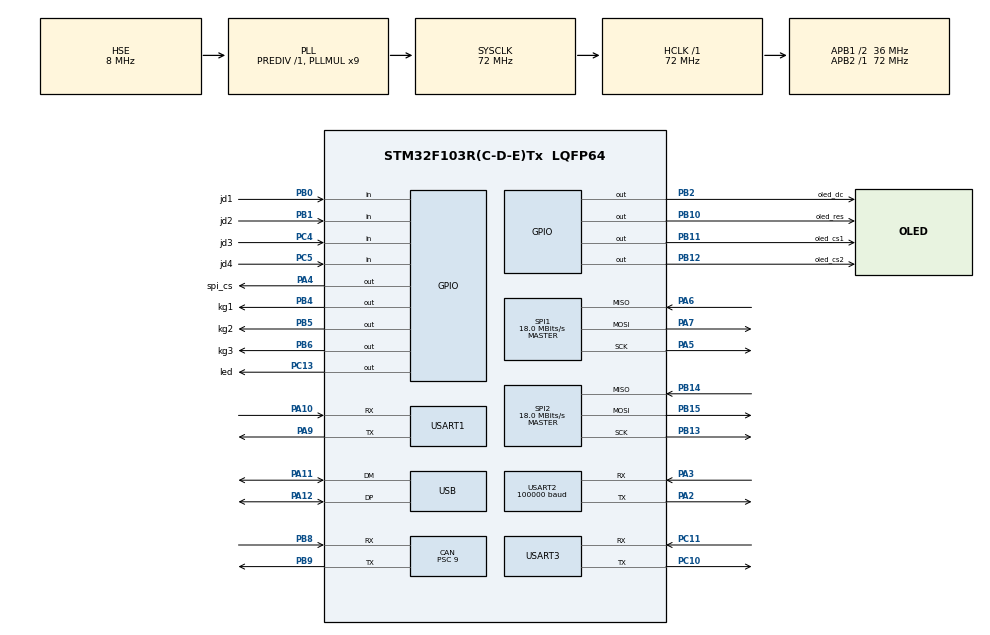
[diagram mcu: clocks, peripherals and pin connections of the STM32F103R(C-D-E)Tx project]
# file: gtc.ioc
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CAN.ABOM=ENABLE
CAN.AWUM=ENABLE
CAN.BS1=CAN_BS1_5TQ
CAN.BS2=CAN_BS2_2TQ
CAN.CalculateBaudRate=500000
CAN.CalculateTimeBit=2000
CAN.CalculateTimeQuantum=250.0
CAN.NART=ENABLE
CAN.Prescaler=9
CAN.SJW=CAN_SJW_1TQ
CAN.TTCM=DISABLE
CAN.TXFP=ENABLE
Dma.Request0=USART1_RX
Dma.Request1=USART1_TX
Dma.Request2=USART2_RX
Dma.Request3=USART3_RX
Dma.Request4=USART3_TX
Dma.USART1_RX.0.Direction=DMA_PERIPH_TO_MEMORY
Dma.USART1_RX.0.Instance=DMA1_Channel5
Dma.USART1_RX.0.MemDataAlignment=DMA_MDATAALIGN_BYTE
Dma.USART1_RX.0.MemInc=DMA_MINC_ENABLE
Dma.USART1_RX.0.Mode=DMA_CIRCULAR
Dma.USART1_RX.0.PeriphDataAlignment=DMA_PDATAALIGN_BYTE
Dma.USART1_RX.0.PeriphInc=DMA_PINC_DISABLE
Dma.USART1_RX.0.Priority=DMA_PRIORITY_LOW
Dma.USART1_TX.1.Direction=DMA_MEMORY_TO_PERIPH
Dma.USART1_TX.1.Instance=DMA1_Channel4
Dma.USART1_TX.1.MemDataAlignment=DMA_MDATAALIGN_BYTE
Dma.USART1_TX.1.MemInc=DMA_MINC_ENABLE
Dma.USART1_TX.1.Mode=DMA_NORMAL
Dma.USART1_TX.1.PeriphDataAlignment=DMA_PDATAALIGN_BYTE
Dma.USART1_TX.1.PeriphInc=DMA_PINC_DISABLE
Dma.USART1_TX.1.Priority=DMA_PRIORITY_LOW
Dma.USART2_RX.2.Direction=DMA_PERIPH_TO_MEMORY
Dma.USART2_RX.2.Instance=DMA1_Channel6
Dma.USART2_RX.2.MemDataAlignment=DMA_MDATAALIGN_BYTE
Dma.USART2_RX.2.MemInc=DMA_MINC_ENABLE
Dma.USART2_RX.2.Mode=DMA_CIRCULAR
Dma.USART2_RX.2.PeriphDataAlignment=DMA_PDATAALIGN_BYTE
Dma.USART2_RX.2.PeriphInc=DMA_PINC_DISABLE
Dma.USART2_RX.2.Priority=DMA_PRIORITY_LOW
Dma.USART3_RX.3.Direction=DMA_PERIPH_TO_MEMORY
Dma.USART3_RX.3.Instance=DMA1_Channel3
Dma.USART3_RX.3.MemDataAlignment=DMA_MDATAALIGN_BYTE
Dma.USART3_RX.3.MemInc=DMA_MINC_ENABLE
Dma.USART3_RX.3.Mode=DMA_NORMAL
Dma.USART3_RX.3.PeriphDataAlignment=DMA_PDATAALIGN_BYTE
Dma.USART3_RX.3.PeriphInc=DMA_PINC_DISABLE
Dma.USART3_RX.3.Priority=DMA_PRIORITY_LOW
Dma.USART3_TX.4.Direction=DMA_MEMORY_TO_PERIPH
Dma.USART3_TX.4.Instance=DMA1_Channel2
Dma.USART3_TX.4.MemDataAlignment=DMA_MDATAALIGN_BYTE
Dma.USART3_TX.4.MemInc=DMA_MINC_ENABLE
Dma.USART3_TX.4.Mode=DMA_CIRCULAR
Dma.USART3_TX.4.PeriphDataAlignment=DMA_PDATAALIGN_BYTE
Dma.USART3_TX.4.PeriphInc=DMA_PINC_DISABLE
Dma.USART3_TX.4.Priority=DMA_PRIORITY_LOW
FREERTOS.Tasks01=systemService,24,256,SystemServiceTask,As weak,NULL,Dynamic,NULL,NULL
FREERTOS.configTOTAL_HEAP_SIZE=5120
Mcu.Family=STM32F1
Mcu.Name=STM32F103R(C-D-E)Tx
Mcu.Package=LQFP64
NVIC.CAN1_RX1_IRQn=true\:5\:0\:false\:false\:true\:true\:true\:true\:true
NVIC.CAN1_SCE_IRQn=true\:5\:0\:false\:false\:true\:true\:true\:true\:true
NVIC.DMA1_Channel2_IRQn=true\:5\:0\:false\:false\:true\:true\:false\:true\:true
NVIC.DMA1_Channel3_IRQn=true\:5\:0\:false\:false\:true\:true\:false\:true\:true
NVIC.DMA1_Channel4_IRQn=true\:5\:0\:false\:false\:true\:true\:false\:true\:true
NVIC.DMA1_Channel5_IRQn=true\:5\:0\:false\:false\:true\:true\:false\:true\:true
NVIC.DMA1_Channel6_IRQn=true\:5\:0\:false\:false\:true\:true\:false\:true\:true
NVIC.PriorityGroup=NVIC_PRIORITYGROUP_4
NVIC.TIM4_IRQn=true\:5\:0\:false\:false\:true\:true\:true\:false\:true
NVIC.TIM6_IRQn=true\:15\:0\:false\:false\:true\:false\:false\:true\:true
NVIC.TimeBase=TIM6_IRQn
NVIC.TimeBaseIP=TIM6
NVIC.USART1_IRQn=true\:5\:0\:true\:false\:true\:true\:true\:true\:true
NVIC.USART2_IRQn=true\:5\:0\:false\:false\:true\:true\:true\:true\:true
NVIC.USART3_IRQn=true\:5\:0\:true\:false\:true\:true\:true\:true\:true
NVIC.USB_HP_CAN1_TX_IRQn=true\:5\:0\:false\:false\:true\:true\:true\:true\:true
NVIC.USB_LP_CAN1_RX0_IRQn=true\:5\:0\:false\:false\:true\:true\:true\:true\:true
PA10.Mode=Asynchronous
PA10.Signal=USART1_RX
PA11.Mode=Device
PA11.Signal=USB_DM
PA12.Mode=Device
PA12.Signal=USB_DP
PA13.Mode=Serial_Wire
PA13.Signal=SYS_JTMS-SWDIO
PA14.Mode=Serial_Wire
PA14.Signal=SYS_JTCK-SWCLK
PA2.Mode=Asynchronous
PA2.Signal=USART2_TX
PA3.Mode=Asynchronous
PA3.Signal=USART2_RX
PA4.GPIO_Label=spi_cs
PA4.Signal=GPIO_Output
PA5.Mode=Full_Duplex_Master
PA5.Signal=SPI1_SCK
PA6.Mode=Full_Duplex_Master
PA6.Signal=SPI1_MISO
PA7.Mode=Full_Duplex_Master
PA7.Signal=SPI1_MOSI
PA9.Mode=Asynchronous
PA9.Signal=USART1_TX
PB0.GPIO_Label=jd1
PB0.GPIO_PuPd=GPIO_PULLDOWN
PB0.Signal=GPIO_Input
PB1.GPIO_Label=jd2
PB1.GPIO_PuPd=GPIO_PULLDOWN
PB1.Signal=GPIO_Input
PB10.GPIO_Label=oled_res
PB10.Signal=GPIO_Output
PB11.GPIO_Label=oled_cs1
PB11.Signal=GPIO_Output
PB12.GPIO_Label=oled_cs2
PB12.Signal=GPIO_Output
PB13.Mode=Full_Duplex_Master
PB13.Signal=SPI2_SCK
PB14.Mode=Full_Duplex_Master
PB14.Signal=SPI2_MISO
PB15.Mode=Full_Duplex_Master
PB15.Signal=SPI2_MOSI
PB2.GPIO_Label=oled_dc
PB2.Signal=GPIO_Output
PB4.GPIO_Label=kg1
PB4.Signal=GPIO_Output
PB5.GPIO_Label=kg2
PB5.Signal=GPIO_Output
PB6.GPIO_Label=kg3
PB6.Signal=GPIO_Output
PB8.Mode=CAN_Activate
PB8.Signal=CAN_RX
PB9.Mode=CAN_Activate
PB9.Signal=CAN_TX
PC10.Mode=Asynchronous
PC10.Signal=USART3_TX
PC11.Mode=Asynchronous
PC11.Signal=USART3_RX
PC13-TAMPER-RTC.GPIO_Label=led
PC13-TAMPER-RTC.GPIO_PuPd=GPIO_PULLUP
PC13-TAMPER-RTC.Signal=GPIO_Output
PC14-OSC32_IN.Mode=LSE-External-Oscillator
PC14-OSC32_IN.Signal=RCC_OSC32_IN
PC15-OSC32_OUT.Mode=LSE-External-Oscillator
PC15-OSC32_OUT.Signal=RCC_OSC32_OUT
PC4.GPIO_Label=jd3
PC4.GPIO_PuPd=GPIO_PULLDOWN
PC4.Signal=GPIO_Input
PC5.GPIO_Label=jd4
PC5.GPIO_PuPd=GPIO_PULLDOWN
PC5.Signal=GPIO_Input
PD0-OSC_IN.Mode=HSE-External-Oscillator
PD0-OSC_IN.Signal=RCC_OSC_IN
PD1-OSC_OUT.Mode=HSE-External-Oscillator
PD1-OSC_OUT.Signal=RCC_OSC_OUT
ProjectManager.HeapSize=0x400
ProjectManager.StackSize=0x800
ProjectManager.TargetToolchain=MDK-ARM V5.32
RCC.AHBFreq_Value=72000000
RCC.APB1CLKDivider=RCC_HCLK_DIV2
RCC.APB1Freq_Value=36000000
RCC.APB1TimFreq_Value=72000000
RCC.APB2Freq_Value=72000000
RCC.APB2TimFreq_Value=72000000
RCC.HCLKFreq_Value=72000000
RCC.PLLMUL=RCC_PLL_MUL9
RCC.PLLSourceVirtual=RCC_PLLSOURCE_HSE
RCC.SYSCLKFreq_VALUE=72000000
RCC.SYSCLKSource=RCC_SYSCLKSOURCE_PLLCLK
RCC.USBFreq_Value=48000000
RCC.USBPrescaler=RCC_USBCLKSOURCE_PLL_DIV1_5
SPI1.BaudRatePrescaler=SPI_BAUDRATEPRESCALER_4
SPI1.CalculateBaudRate=18.0 MBits/s
SPI1.Direction=SPI_DIRECTION_2LINES
SPI1.Mode=SPI_MODE_MASTER
SPI1.VirtualType=VM_MASTER
SPI2.CalculateBaudRate=18.0 MBits/s
SPI2.Direction=SPI_DIRECTION_2LINES
SPI2.Mode=SPI_MODE_MASTER
SPI2.VirtualType=VM_MASTER
TIM4.Period=500
TIM4.Prescaler=7200-1
USART1.VirtualMode=VM_ASYNC
USART2.BaudRate=100000
USART2.Mode=MODE_RX
USART2.Parity=PARITY_EVEN
USART2.StopBits=STOPBITS_2
USART2.VirtualMode=VM_ASYNC
USART3.VirtualMode=VM_ASYNC
VP_FREERTOS_VS_CMSIS_V2.Mode=CMSIS_V2
VP_SYS_VS_tim6.Mode=TIM6
VP_TIM4_VS_ClockSourceINT.Mode=Internal
board=custom

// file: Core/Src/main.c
/* USER CODE BEGIN Header */
/**
  ******************************************************************************
  * @file           : main.c
  * @brief          : Main program body
  ******************************************************************************
  * @attention
  *
  * Copyright (c) 2024 STMicroelectronics.
  * All rights reserved.
  *
  * This software is licensed under terms that can be found in the LICENSE file
  * in the root directory of this software component.
  * If no LICENSE file comes with this software, it is provided AS-IS.
  *
  ******************************************************************************
  */
/* USER CODE END Header */
#include "main.h"
#include "cmsis_os.h"
#include "can.h"
#include "dma.h"
#include "spi.h"
#include "tim.h"
#include "usart.h"
#include "usb.h"
#include "gpio.h"

void SystemClock_Config(void);
void MX_FREERTOS_Init(void);

int main(void)
{

  /* MCU Configuration--------------------------------------------------------*/

  /* Reset of all peripherals, Initializes the Flash interface and the Systick. */
  HAL_Init();

  /* Configure the system clock */
  SystemClock_Config();

  /* Initialize all configured peripherals */
  MX_GPIO_Init();
  MX_DMA_Init();
  MX_CAN_Init();
  MX_SPI1_Init();
  MX_SPI2_Init();
  MX_USART1_UART_Init();
  MX_USART2_UART_Init();
  MX_USB_PCD_Init();
  MX_USART3_UART_Init();
  MX_TIM4_Init();

  /* Init scheduler */
  osKernelInitialize();

  /* Call init function for freertos objects (in freertos.c) */
  MX_FREERTOS_Init();

  /* Start scheduler */
  osKernelStart();

  /* We should never get here as control is now taken by the scheduler */
  /* Infinite loop */
  while (1)
  {

  }
}

void SystemClock_Config(void)
{
  RCC_OscInitTypeDef RCC_OscInitStruct = {0};
  RCC_ClkInitTypeDef RCC_ClkInitStruct = {0};
  RCC_PeriphCLKInitTypeDef PeriphClkInit = {0};

  /** Initializes the RCC Oscillators according to the specified parameters
  * in the RCC_OscInitTypeDef structure.
  */
  RCC_OscInitStruct.OscillatorType = RCC_OSCILLATORTYPE_HSE;
  RCC_OscInitStruct.HSEState = RCC_HSE_ON;
  RCC_OscInitStruct.HSEPredivValue = RCC_HSE_PREDIV_DIV1;
  RCC_OscInitStruct.HSIState = RCC_HSI_ON;
  RCC_OscInitStruct.PLL.PLLState = RCC_PLL_ON;
  RCC_OscInitStruct.PLL.PLLSource = RCC_PLLSOURCE_HSE;
  RCC_OscInitStruct.PLL.PLLMUL = RCC_PLL_MUL9;
  if (HAL_RCC_OscConfig(&RCC_OscInitStruct) != HAL_OK)
  {
    Error_Handler();
  }

  /** Initializes the CPU, AHB and APB buses clocks
  */
  RCC_ClkInitStruct.ClockType = RCC_CLOCKTYPE_HCLK|RCC_CLOCKTYPE_SYSCLK
                              |RCC_CLOCKTYPE_PCLK1|RCC_CLOCKTYPE_PCLK2;
  RCC_ClkInitStruct.SYSCLKSource = RCC_SYSCLKSOURCE_PLLCLK;
  RCC_ClkInitStruct.AHBCLKDivider = RCC_SYSCLK_DIV1;
  RCC_ClkInitStruct.APB1CLKDivider = RCC_HCLK_DIV2;
  RCC_ClkInitStruct.APB2CLKDivider = RCC_HCLK_DIV1;

  if (HAL_RCC_ClockConfig(&RCC_ClkInitStruct, FLASH_LATENCY_2) != HAL_OK)
  {
    Error_Handler();
  }
  PeriphClkInit.PeriphClockSelection = RCC_PERIPHCLK_USB;
  PeriphClkInit.UsbClockSelection = RCC_USBCLKSOURCE_PLL_DIV1_5;
  if (HAL_RCCEx_PeriphCLKConfig(&PeriphClkInit) != HAL_OK)
  {
    Error_Handler();
  }
}

void HAL_TIM_PeriodElapsedCallback(TIM_HandleTypeDef *htim)
{
  if (htim->Instance == TIM6) {
    HAL_IncTick();
  }
}

void Error_Handler(void)
{
  __disable_irq();
  while (1)
  {
  }
}

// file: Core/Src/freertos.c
/* USER CODE BEGIN Header */
/**
  ******************************************************************************
  * File Name          : freertos.c
  * Description        : Code for freertos applications
  ******************************************************************************
  * @attention
  *
  * Copyright (c) 2024 STMicroelectronics.
  * All rights reserved.
  *
  * This software is licensed under terms that can be found in the LICENSE file
  * in the root directory of this software component.
  * If no LICENSE file comes with this software, it is provided AS-IS.
  *
  ******************************************************************************
  */
/* USER CODE END Header */

#include "FreeRTOS.h"
#include "task.h"
#include "main.h"
#include "cmsis_os.h"

/* USER CODE BEGIN Includes */
#include "usart.h"
/* USER CODE END Includes */

/* Definitions for systemService */
osThreadId_t systemServiceHandle;
const osThreadAttr_t systemService_attributes = {
  .name = "systemService",
  .stack_size = 256 * 4,
  .priority = (osPriority_t) osPriorityNormal,
};

/* USER CODE BEGIN FunctionPrototypes */
void systemLedTask(void * pvParameters);

TaskHandle_t systemledHandle = NULL;
/* USER CODE END FunctionPrototypes */

void SystemServiceTask(void *argument);

void MX_FREERTOS_Init(void); /* (MISRA C 2004 rule 8.1) */

void MX_FREERTOS_Init(void) {

  /* Create the thread(s) */
  /* creation of systemService */
  systemServiceHandle = osThreadNew(SystemServiceTask, NULL, &systemService_attributes);

  /* USER CODE BEGIN RTOS_EVENTS */
  /* add events, ... */
  xTaskCreate(systemLedTask, "systemled", 128, NULL, 1, &systemledHandle);
  /* USER CODE END RTOS_EVENTS */

}

__weak void SystemServiceTask(void *argument)
{
  /* USER CODE BEGIN SystemServiceTask */
  /* Infinite loop */
  for(;;)
  {
	  HAL_GPIO_TogglePin(led_GPIO_Port, led_Pin);
	  vTaskDelay(100);
  }
  /* USER CODE END SystemServiceTask */
}

/* USER CODE BEGIN Application */
void systemLedTask(void * pvParameters)
{
	for(;;)
	{
		HAL_GPIO_TogglePin(led_GPIO_Port, led_Pin);
		osDelay(500);
	}
}
/* USER CODE END Application */
